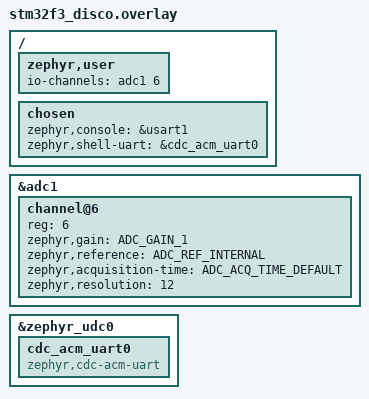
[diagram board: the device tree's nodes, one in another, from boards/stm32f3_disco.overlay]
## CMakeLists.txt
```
# SPDX-License-Identifier: Apache-2.0

cmake_minimum_required(VERSION 3.20.0)
find_package(Zephyr REQUIRED HINTS $ENV{ZEPHYR_BASE})
project(shell_module)

target_sources(app PRIVATE src/main.c src/adc_sampling.c src/calc_avg.c src/app_shellcmd_adc.c)
target_sources_ifdef(CONFIG_SHELL_BACKEND_SERIAL app PRIVATE src/uart_reinit.c)

cmake_minimum_required(VERSION 3.20.0)

find_package(Zephyr REQUIRED HINTS $ENV{ZEPHYR_BASE})
project(adc)
```

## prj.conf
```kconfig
CONFIG_PRINTK=y
CONFIG_SHELL=y
CONFIG_LOG=y
CONFIG_INIT_STACKS=y

CONFIG_THREAD_STACK_INFO=y
CONFIG_KERNEL_SHELL=y
CONFIG_THREAD_MONITOR=y
CONFIG_BOOT_BANNER=n
CONFIG_THREAD_NAME=y
CONFIG_DEVICE_SHELL=y
CONFIG_POSIX_CLOCK=y
CONFIG_DATE_SHELL=y
CONFIG_THREAD_RUNTIME_STATS=y
CONFIG_THREAD_RUNTIME_STATS_USE_TIMING_FUNCTIONS=y
CONFIG_STATS=y
CONFIG_STATS_SHELL=y

#CONFIG_SHELL_BACKEND_SERIAL_CHECK_DTR=y
#CONFIG_SHELL_BACKEND_SERIAL_INIT_PRIORITY=51

CONFIG_ADC=y

# ----------------- CONSOLE
CONFIG_CONSOLE=y
CONFIG_SERIAL=y
CONFIG_UART_LINE_CTRL=y
CONFIG_UART_INTERRUPT_DRIVEN=y
CONFIG_UART_CONSOLE=y
CONFIG_SHELL_LOG_BACKEND=n
CONFIG_LOG_BACKEND_UART=y

# ----------------- USB
CONFIG_USB_DEVICE_STACK=y
CONFIG_USB_DEVICE_PRODUCT="Zephyr USB shell sample"
CONFIG_USB_DEVICE_PID=0x0001
CONFIG_USB_DEVICE_INITIALIZE_AT_BOOT=n
CONFIG_USB_DRIVER_LOG_LEVEL_ERR=y

#------------------ Compiler configurations
CONFIG_NEWLIB_LIBC=y
CONFIG_NEWLIB_LIBC_FLOAT_PRINTF=y
CONFIG_CBPRINTF_FP_SUPPORT=y
```

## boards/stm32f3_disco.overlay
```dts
/* Copyright (c) 2021 STMicroelectronics
   SPDX-License-Identifier: Apache-2.0 */

 / {
	zephyr,user {
		/* adjust channel number according to pinmux in board.dts */
		io-channels = <&adc1 6>/*,<&adc1 6>*/;
		
	};
	
	chosen {
	        zephyr,console = &usart1;
		zephyr,shell-uart = &cdc_acm_uart0;
	};
};

&adc1 {
	#address-cells = <1>;
	#size-cells = <0>;
	
	/*channel@7 {
		reg = <7>;
		zephyr,gain = "ADC_GAIN_1";
		zephyr,reference = "ADC_REF_INTERNAL";
		zephyr,acquisition-time = <ADC_ACQ_TIME_DEFAULT>;
		zephyr,resolution = <12>;
	};*/
	
	channel@6 {
		reg = <6>;
		zephyr,gain = "ADC_GAIN_1";
		zephyr,reference = "ADC_REF_INTERNAL";
		zephyr,acquisition-time = <ADC_ACQ_TIME_DEFAULT>;
		zephyr,resolution = <12>;
	};

        
};

&zephyr_udc0 {
	cdc_acm_uart0: cdc_acm_uart0 {
		compatible = "zephyr,cdc-acm-uart";
	};
};
```

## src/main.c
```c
#include <inttypes.h>
#include <stddef.h>
#include <stdint.h>
#include <zephyr/device.h>
#include <zephyr/devicetree.h>
#include <zephyr/drivers/adc.h>
#include <zephyr/kernel.h>
#include <zephyr/sys/printk.h>
#include <zephyr/sys/util.h>
#include <string.h>
#include <time.h>
#include <stdio.h>
#include <zephyr/kernel.h>
#include <zephyr/shell/shell.h>
#include <version.h>
#include <zephyr/logging/log.h>
#include <stdlib.h>
#include <zephyr/drivers/uart.h>
#include <zephyr/usb/usb_device.h>
#include <ctype.h>
#ifdef CONFIG_ARCH_POSIX
#include <unistd.h>
#else
#include <zephyr/posix/unistd.h>
#endif
#if !DT_NODE_EXISTS(DT_PATH(zephyr_user)) || \
	!DT_NODE_HAS_PROP(DT_PATH(zephyr_user), io_channels)
#error "No suitable devicetree overlay specified"
#endif

#define DT_SPEC_AND_COMMA(node_id, prop, idx) \
	ADC_DT_SPEC_GET_BY_IDX(node_id, idx),

#include "adc_sampling.h"

/* Data of ADC io-channels specified in devicetree. */

struct adc_dt_spec adc_channels[] = {
	DT_FOREACH_PROP_ELEM(DT_PATH(zephyr_user), io_channels,
			     DT_SPEC_AND_COMMA)
};

int main(void)
{
#if DT_NODE_HAS_COMPAT(DT_CHOSEN(zephyr_shell_uart), zephyr_cdc_acm_uart)
	const struct device *dev;
        dev = DEVICE_DT_GET(DT_CHOSEN(zephyr_shell_uart));
	if (!device_is_ready(dev) || usb_enable(NULL)) 
	{
		return 0;
	}
#endif
        uint32_t dtr = 0;
        while (!dtr) 
	{
	  int err;
	  //float p_avg_mv=0;
	  //uint32_t count = 0;
	  uint16_t buf;
	  struct adc_sequence sequence = {
		  .buffer = &buf,
		  /* buffer size in bytes, not number of samples */
		  .buffer_size = sizeof(buf),
	  };

	  /* Configure channels individually prior to sampling. */
	  for (size_t i = 0U; i < ARRAY_SIZE(adc_channels); i++) {
		  if (!adc_is_ready_dt(&adc_channels[i])) {
			  printk("ADC controller device %s not ready\n", adc_channels[i].dev->name);
			  return 0;
		  }

		  err = adc_channel_setup_dt(&adc_channels[i]);
		  if (err < 0) {
			  printk("Could not setup channel #%d (%d)\n", i, err);
			  return 0;
		  }
	  }

	  while (1) {
		  /*printk("ADC reading[%u]:\n", count++);*/
		  /*for (*/size_t i = 0U;/*; i < ARRAY_SIZE(adc_channels); i++) {*/
			  int32_t val_mv;
			  int32_t adc_raw =0;

			  /*printk("- %s, channel %d: \n",
			         adc_channels[i].dev->name,
			         adc_channels[i].channel_id);*/

			  (void)adc_sequence_init_dt(&adc_channels[i], &sequence);

			  err = adc_read(adc_channels[i].dev, &sequence);
			  if (err < 0) {
				  printk("Could not read (%d)\n", err);
				  continue;
			  }
			  val_mv = (int32_t)buf;
			  //printk("RAW ADC = %d\n", val_mv);
			  adc_raw = val_mv;
			  //printk("RAW ADC = %d\n", adc_raw);
			  //printk("VAL_MV ADC = %d\n", val_mv);
			  err = adc_raw_to_millivolts_dt(&adc_channels[i], &val_mv);
			  
			  /* conversion to mV may not be supported, skip if not */
			  if (err < 0) {
				  printk(" (value in mV not available)\n");
			  } else {
			          //printk("While(1)adc=%dmV\n", val_mv);
			          adc_sampling(val_mv,adc_raw);
			          //adc_sampling(adc_raw);
				  //printk("Avg adc=%0.2fmV\n", p_avg_mv);
			  }
			  /*}*/

		  k_sleep(K_MSEC(10));
	  }
	}
	return 0;
}
```

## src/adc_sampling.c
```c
#include <inttypes.h>
#include <stddef.h>
#include <stdint.h>
#include <zephyr/device.h>
#include <zephyr/devicetree.h>
#include <zephyr/drivers/adc.h>
#include <zephyr/kernel.h>
#include <zephyr/sys/printk.h>
#include <zephyr/sys/util.h>
#include <string.h>
#include <time.h>
#include <stdio.h>
#include <zephyr/kernel.h>
#include <zephyr/shell/shell.h>
#include <version.h>
#include <zephyr/logging/log.h>
#include <stdlib.h>
#include <zephyr/drivers/uart.h>
#include <zephyr/usb/usb_device.h>
#include <ctype.h>
#ifdef CONFIG_ARCH_POSIX
#include <unistd.h>
#else
#include <zephyr/posix/unistd.h>
#endif

#include "calc_avg.h"

#define LOOP_DELAY 10
#define DEFAULT_PRINT_INTERVAL 1000
#define DEFAULT_SAMPLE_COUNT (DEFAULT_PRINT_INTERVAL / LOOP_DELAY)

#define RESET 0
#define LOW 0
#define HIGH 1


static int adc_state = LOW;
static int prnt_intr = DEFAULT_PRINT_INTERVAL;
static int sample_count = DEFAULT_SAMPLE_COUNT;

extern struct adc_dt_spec adc_channels[];
size_t i;

static int sampling_counter,raw_counter = 0;
static float return_avg = 0;
static int adc_sample[1000]={0};
static int index,raw_adc_total = 0;

int adc_enable ()
{
  adc_state = HIGH;
  return 0;
}

int adc_disable ()
{
  adc_state = LOW;
  sampling_counter = RESET;
  prnt_intr = DEFAULT_PRINT_INTERVAL;
  sample_count = DEFAULT_SAMPLE_COUNT;
  return 0;
}

int print_interval (int interval_ms)
{
 prnt_intr = interval_ms;
 sampling_counter = RESET;
 raw_counter = RESET;
 sample_count = RESET;
 sample_count = DEFAULT_SAMPLE_COUNT;
 sample_count = prnt_intr/LOOP_DELAY;
 return 0;
}

int print_interval_get (int *p_prnt_interval_ms)
{
  *p_prnt_interval_ms = prnt_intr;
  return 0;
}

int adc_sampling (int32_t val_mv, int32_t adc_raw)
{
    if (adc_state == HIGH){
		if (sampling_counter == prnt_intr && raw_counter == sample_count){
			float raw_adc_avg = raw_adc_total/sample_count;
			return_avg = calc_avg(adc_sample,sample_count);
			printk("- %s, channel %d: ", adc_channels[i].dev->name, adc_channels[i].channel_id);
			printk("raw = %dbin value = %dmV\n",(int)raw_adc_avg, (int)return_avg);
			index = RESET;
			sampling_counter = RESET;
			raw_adc_total = RESET;
			raw_counter = RESET;
			return 0;
		}
		else {
			adc_sample[index] = val_mv;
			index ++;
			if(raw_counter ==  sample_count);
			else {
				raw_adc_total = raw_adc_total + adc_raw;
				raw_counter ++;
			}
			sampling_counter = sampling_counter + LOOP_DELAY;
			return 0;
		}
  }
  else {
	  return 0;
  }
}
```

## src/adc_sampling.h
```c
#ifndef ADC_SAMPLING_H_INCLUDED
#define ADC_SAMPLING_H_INCLUDED

int adc_enable ();
int adc_disable ();
int print_interval (int interval_ms);
int print_interval_get (int *p_prnt_interval_ms);
int adc_sampling (int32_t val_mv, int32_t adc_raw);

#endif 
```

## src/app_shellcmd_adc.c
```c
#include <inttypes.h>
#include <stddef.h>
#include <stdint.h>
#include <zephyr/device.h>
#include <zephyr/devicetree.h>
#include <zephyr/drivers/adc.h>
#include <zephyr/kernel.h>
#include <zephyr/sys/printk.h>
#include <zephyr/sys/util.h>
#include <string.h>
#include <time.h>
#include <stdio.h>
#include <zephyr/kernel.h>
#include <zephyr/shell/shell.h>
#include <version.h>
#include <zephyr/logging/log.h>
#include <stdlib.h>
#include <zephyr/drivers/uart.h>
#include <zephyr/usb/usb_device.h>
#include <ctype.h>
#ifdef CONFIG_ARCH_POSIX
#include <unistd.h>
#else
#include <zephyr/posix/unistd.h>
#endif
#include <unistd.h>
	
#include "adc_sampling.h"
#include "calc_avg.h"

#define DEFAULT_PRINT_INTERVAL 1000

extern struct adc_dt_spec adc_channels[];
static int i = 0;
static int prnt_var = 0;

static int shellcmd_adc_start(const struct shell *shell, size_t argc, char **argv) {
	ARG_UNUSED(argc);
	ARG_UNUSED(argv);

	int ret = adc_enable();
	if (!ret) {
		shell_print(shell, "OK");
		printk("- %s, channel %d: ",
			       adc_channels[i].dev->name,
			       adc_channels[i].channel_id);
		printk("ADC enabled\n");
	}
	else {
		shell_print(shell, "ERR");
	}
	return ret;
}

static int shellcmd_adc_stop(const struct shell *shell, size_t argc, char **argv) {
	ARG_UNUSED(argc);
	ARG_UNUSED(argv);

	int ret = adc_disable();
	if (!ret) {
		shell_print(shell, "OK");
		printk("ADC disabled\n");
	}
	else {
		shell_print(shell, "ERR");
	}
	return ret;
}

static int shellcmd_print_set_interval(const struct shell *shell, size_t argc, char **argv)
{
	ARG_UNUSED(argc);
	ARG_UNUSED(argv);

	prnt_var = strtol(argv[1], NULL, 10);
	shell_print(shell,"Print interval = %d ms", prnt_var);
	printk("ADC print interval set = %d ms\n", prnt_var);
	int ret = print_interval(prnt_var);

	if (!ret)	shell_print(shell, "OK");
	else		shell_print(shell, "ERR");

	return ret;
}

static int shellcmd_print_get_interval(const struct shell *shell, size_t argc, char **argv)
{
	ARG_UNUSED(argc);
	ARG_UNUSED(argv);
        
    int p_prnt_interval_ms = 0;
        
	int ret = print_interval_get(&p_prnt_interval_ms);
	if (!ret){	
	    shell_print(shell, "OK");
	    shell_print(shell,"ADC print interval set = %d ms", p_prnt_interval_ms);
	    printk("ADC print interval set = %d ms\n", p_prnt_interval_ms);
	}
	else		shell_print(shell, "ERR");

	return ret;
}

SHELL_STATIC_SUBCMD_SET_CREATE(adc_log_subcmds,
		SHELL_CMD(start, NULL, "Adc enable", shellcmd_adc_start),
		SHELL_CMD(stop, NULL, "Adc disable", shellcmd_adc_stop),
		SHELL_CMD(prnt_intr_get, NULL, "print interval set in ms", shellcmd_print_get_interval),
		SHELL_CMD_ARG(prnt_intr_set, NULL, "print interval set in ms", shellcmd_print_set_interval, 2, 0),
		SHELL_SUBCMD_SET_END /* Array terminated. */
		);
SHELL_CMD_REGISTER(adc_log, &adc_log_subcmds, "ADC sub commands", NULL);
```

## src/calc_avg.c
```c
#include <inttypes.h>
#include <stddef.h>
#include <stdint.h>
#include <zephyr/device.h>
#include <zephyr/devicetree.h>
#include <zephyr/drivers/adc.h>
#include <zephyr/kernel.h>
#include <zephyr/sys/printk.h>
#include <zephyr/sys/util.h>
#include <string.h>
#include <time.h>
#include <stdio.h>
#include <zephyr/kernel.h>
#include <zephyr/shell/shell.h>
#include <version.h>
#include <zephyr/logging/log.h>
#include <stdlib.h>
#include <zephyr/drivers/uart.h>
#include <zephyr/usb/usb_device.h>
#include <ctype.h>
#ifdef CONFIG_ARCH_POSIX
#include <unistd.h>
#else
#include <zephyr/posix/unistd.h>
#endif

float calc_avg(int adc_sample[], int sample_count)
{
  int index,total_value = 0;
  float adc_avg=0;
  
  for (index=0;index<sample_count;index++){
  total_value += adc_sample[index];
  }
  adc_avg = (float)total_value/sample_count;
  //printk("Avg adc=%0.2fmV\n", adc_avg);
  
  return adc_avg;
}
```

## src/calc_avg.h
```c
#ifndef CALC_AVG_H_INCLUDED
#define CALC_AVG_H_INCLUDED

float calc_avg(int adc_sample[], int sample_count);

#endif 
```
